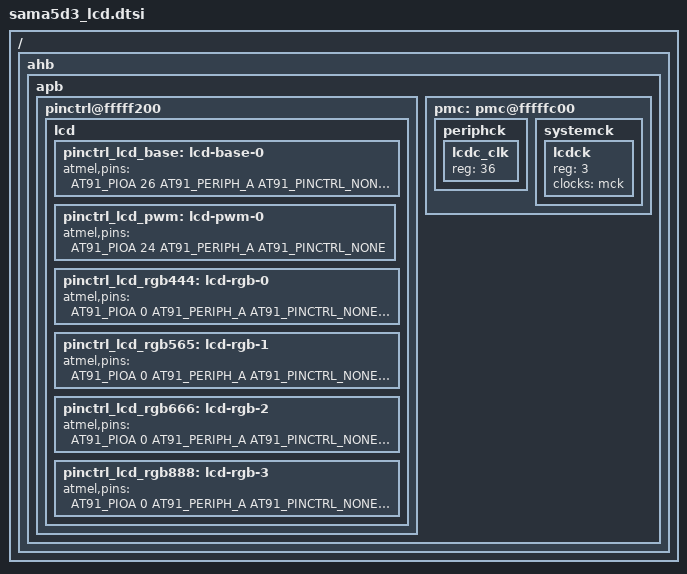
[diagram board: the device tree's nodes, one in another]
/*
 * sama5d3_lcd.dtsi - Device Tree Include file for SAMA5D3 SoC with
 * LCD support
 *
 * Copyright (C) 2013 Boris BREZILLON <b.brezillon@overkiz.com>
 *
 * Licensed under GPLv2.
 */

#include <dt-bindings/pinctrl/at91.h>
#include <dt-bindings/interrupt-controller/irq.h>

/ {
	ahb {
		apb {
			pinctrl@fffff200 {
				lcd {
					pinctrl_lcd_base: lcd-base-0 {
						atmel,pins =
							<AT91_PIOA 26 AT91_PERIPH_A AT91_PINCTRL_NONE	/* LCDVSYNC */
							 AT91_PIOA 27 AT91_PERIPH_A AT91_PINCTRL_NONE	/* LCDHSYNC */
							 AT91_PIOA 25 AT91_PERIPH_A AT91_PINCTRL_NONE	/* LCDDISP */
							 AT91_PIOA 29 AT91_PERIPH_A AT91_PINCTRL_NONE	/* LCDDEN */
							 AT91_PIOA 28 AT91_PERIPH_A AT91_PINCTRL_NONE>;	/* LCDPCK */
					};

					pinctrl_lcd_pwm: lcd-pwm-0 {
						atmel,pins = <AT91_PIOA 24 AT91_PERIPH_A AT91_PINCTRL_NONE>;	/* LCDPWM */
					};

					pinctrl_lcd_rgb444: lcd-rgb-0 {
						atmel,pins =
							<AT91_PIOA 0 AT91_PERIPH_A AT91_PINCTRL_NONE	/* LCDD0 pin */
							 AT91_PIOA 1 AT91_PERIPH_A AT91_PINCTRL_NONE	/* LCDD1 pin */
							 AT91_PIOA 2 AT91_PERIPH_A AT91_PINCTRL_NONE	/* LCDD2 pin */
							 AT91_PIOA 3 AT91_PERIPH_A AT91_PINCTRL_NONE	/* LCDD3 pin */
							 AT91_PIOA 4 AT91_PERIPH_A AT91_PINCTRL_NONE	/* LCDD4 pin */
							 AT91_PIOA 5 AT91_PERIPH_A AT91_PINCTRL_NONE	/* LCDD5 pin */
							 AT91_PIOA 6 AT91_PERIPH_A AT91_PINCTRL_NONE	/* LCDD6 pin */
							 AT91_PIOA 7 AT91_PERIPH_A AT91_PINCTRL_NONE	/* LCDD7 pin */
							 AT91_PIOA 8 AT91_PERIPH_A AT91_PINCTRL_NONE	/* LCDD8 pin */
							 AT91_PIOA 9 AT91_PERIPH_A AT91_PINCTRL_NONE	/* LCDD9 pin */
							 AT91_PIOA 10 AT91_PERIPH_A AT91_PINCTRL_NONE	/* LCDD10 pin */
							 AT91_PIOA 11 AT91_PERIPH_A AT91_PINCTRL_NONE>;	/* LCDD11 pin */
					};

					pinctrl_lcd_rgb565: lcd-rgb-1 {
						atmel,pins =
							<AT91_PIOA 0 AT91_PERIPH_A AT91_PINCTRL_NONE	/* LCDD0 pin */
							 AT91_PIOA 1 AT91_PERIPH_A AT91_PINCTRL_NONE	/* LCDD1 pin */
							 AT91_PIOA 2 AT91_PERIPH_A AT91_PINCTRL_NONE	/* LCDD2 pin */
							 AT91_PIOA 3 AT91_PERIPH_A AT91_PINCTRL_NONE	/* LCDD3 pin */
							 AT91_PIOA 4 AT91_PERIPH_A AT91_PINCTRL_NONE	/* LCDD4 pin */
							 AT91_PIOA 5 AT91_PERIPH_A AT91_PINCTRL_NONE	/* LCDD5 pin */
							 AT91_PIOA 6 AT91_PERIPH_A AT91_PINCTRL_NONE	/* LCDD6 pin */
							 AT91_PIOA 7 AT91_PERIPH_A AT91_PINCTRL_NONE	/* LCDD7 pin */
							 AT91_PIOA 8 AT91_PERIPH_A AT91_PINCTRL_NONE	/* LCDD8 pin */
							 AT91_PIOA 9 AT91_PERIPH_A AT91_PINCTRL_NONE	/* LCDD9 pin */
							 AT91_PIOA 10 AT91_PERIPH_A AT91_PINCTRL_NONE	/* LCDD10 pin */
							 AT91_PIOA 11 AT91_PERIPH_A AT91_PINCTRL_NONE	/* LCDD11 pin */
							 AT91_PIOA 12 AT91_PERIPH_A AT91_PINCTRL_NONE	/* LCDD12 pin */
							 AT91_PIOA 13 AT91_PERIPH_A AT91_PINCTRL_NONE	/* LCDD13 pin */
							 AT91_PIOA 14 AT91_PERIPH_A AT91_PINCTRL_NONE	/* LCDD14 pin */
							 AT91_PIOA 15 AT91_PERIPH_A AT91_PINCTRL_NONE>;	/* LCDD15 pin */
					};

					pinctrl_lcd_rgb666: lcd-rgb-2 {
						atmel,pins =
							<AT91_PIOA 0 AT91_PERIPH_A AT91_PINCTRL_NONE	/* LCDD0 pin */
							 AT91_PIOA 1 AT91_PERIPH_A AT91_PINCTRL_NONE	/* LCDD1 pin */
							 AT91_PIOA 2 AT91_PERIPH_A AT91_PINCTRL_NONE	/* LCDD2 pin */
							 AT91_PIOA 3 AT91_PERIPH_A AT91_PINCTRL_NONE	/* LCDD3 pin */
							 AT91_PIOA 4 AT91_PERIPH_A AT91_PINCTRL_NONE	/* LCDD4 pin */
							 AT91_PIOA 5 AT91_PERIPH_A AT91_PINCTRL_NONE	/* LCDD5 pin */
							 AT91_PIOA 6 AT91_PERIPH_A AT91_PINCTRL_NONE	/* LCDD6 pin */
							 AT91_PIOA 7 AT91_PERIPH_A AT91_PINCTRL_NONE	/* LCDD7 pin */
							 AT91_PIOA 8 AT91_PERIPH_A AT91_PINCTRL_NONE	/* LCDD8 pin */
							 AT91_PIOA 9 AT91_PERIPH_A AT91_PINCTRL_NONE	/* LCDD9 pin */
							 AT91_PIOA 10 AT91_PERIPH_A AT91_PINCTRL_NONE	/* LCDD10 pin */
							 AT91_PIOA 11 AT91_PERIPH_A AT91_PINCTRL_NONE	/* LCDD11 pin */
							 AT91_PIOA 12 AT91_PERIPH_A AT91_PINCTRL_NONE	/* LCDD12 pin */
							 AT91_PIOA 13 AT91_PERIPH_A AT91_PINCTRL_NONE	/* LCDD13 pin */
							 AT91_PIOA 14 AT91_PERIPH_A AT91_PINCTRL_NONE	/* LCDD14 pin */
							 AT91_PIOA 15 AT91_PERIPH_A AT91_PINCTRL_NONE	/* LCDD15 pin */
							 AT91_PIOC 14 AT91_PERIPH_C AT91_PINCTRL_NONE	/* LCDD16 pin */
							 AT91_PIOC 13 AT91_PERIPH_C AT91_PINCTRL_NONE>;	/* LCDD17 pin */
					};

					pinctrl_lcd_rgb888: lcd-rgb-3 {
						atmel,pins =
							<AT91_PIOA 0 AT91_PERIPH_A AT91_PINCTRL_NONE	/* LCDD0 pin */
							 AT91_PIOA 1 AT91_PERIPH_A AT91_PINCTRL_NONE	/* LCDD1 pin */
							 AT91_PIOA 2 AT91_PERIPH_A AT91_PINCTRL_NONE	/* LCDD2 pin */
							 AT91_PIOA 3 AT91_PERIPH_A AT91_PINCTRL_NONE	/* LCDD3 pin */
							 AT91_PIOA 4 AT91_PERIPH_A AT91_PINCTRL_NONE	/* LCDD4 pin */
							 AT91_PIOA 5 AT91_PERIPH_A AT91_PINCTRL_NONE	/* LCDD5 pin */
							 AT91_PIOA 6 AT91_PERIPH_A AT91_PINCTRL_NONE	/* LCDD6 pin */
							 AT91_PIOA 7 AT91_PERIPH_A AT91_PINCTRL_NONE	/* LCDD7 pin */
							 AT91_PIOA 8 AT91_PERIPH_A AT91_PINCTRL_NONE	/* LCDD8 pin */
							 AT91_PIOA 9 AT91_PERIPH_A AT91_PINCTRL_NONE	/* LCDD9 pin */
							 AT91_PIOA 10 AT91_PERIPH_A AT91_PINCTRL_NONE	/* LCDD10 pin */
							 AT91_PIOA 11 AT91_PERIPH_A AT91_PINCTRL_NONE	/* LCDD11 pin */
							 AT91_PIOA 12 AT91_PERIPH_A AT91_PINCTRL_NONE	/* LCDD12 pin */
							 AT91_PIOA 13 AT91_PERIPH_A AT91_PINCTRL_NONE	/* LCDD13 pin */
							 AT91_PIOA 14 AT91_PERIPH_A AT91_PINCTRL_NONE	/* LCDD14 pin */
							 AT91_PIOA 15 AT91_PERIPH_A AT91_PINCTRL_NONE	/* LCDD15 pin */
							 AT91_PIOC 14 AT91_PERIPH_C AT91_PINCTRL_NONE	/* LCDD16 pin */
							 AT91_PIOC 13 AT91_PERIPH_C AT91_PINCTRL_NONE	/* LCDD17 pin */
							 AT91_PIOC 12 AT91_PERIPH_C AT91_PINCTRL_NONE	/* LCDD18 pin */
							 AT91_PIOC 11 AT91_PERIPH_C AT91_PINCTRL_NONE	/* LCDD19 pin */
							 AT91_PIOC 10 AT91_PERIPH_C AT91_PINCTRL_NONE	/* LCDD20 pin */
							 AT91_PIOC 15 AT91_PERIPH_C AT91_PINCTRL_NONE	/* LCDD21 pin */
							 AT91_PIOE 27 AT91_PERIPH_C AT91_PINCTRL_NONE	/* LCDD22 pin */
							 AT91_PIOE 28 AT91_PERIPH_C AT91_PINCTRL_NONE>;	/* LCDD23 pin */
					};
				};
			};

			pmc: pmc@fffffc00 {
				periphck {
					lcdc_clk: lcdc_clk {
						#clock-cells = <0>;
						reg = <36>;
					};
				};

				systemck {
					lcdck: lcdck {
						#clock-cells = <0>;
						reg = <3>;
						clocks = <&mck>;
					};
				};
			};
		};
	};
};
